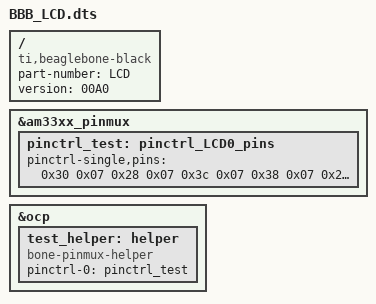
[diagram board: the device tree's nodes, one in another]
/dts-v1/;
/plugin/;
/{
   compatible  = "ti,beaglebone-black";
   part-number = "LCD";
   version     = "00A0";

   fragment@0 {
	target = <&am33xx_pinmux>;
	__overlay__ {
	   pinctrl_test: pinctrl_LCD0_pins {
		pinctrl-single,pins =<
			0x30 0x07
			0x28 0x07
			0x3c 0x07
			0x38 0x07
			0x2c 0x07
			0x8c 0x07
		>;
	   };
	};
   };

   fragment@1 {
	target = <&ocp>;
	__overlay__ {
	   test_helper: helper {
		compatible = "bone-pinmux-helper";
		pinctrl-names = "default";
		pinctrl-0 = <&pinctrl_test>;
		status = "okay";
	   };
	};
   };
};
